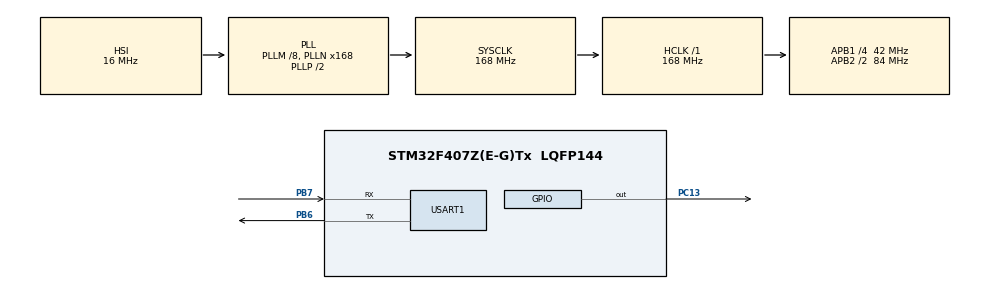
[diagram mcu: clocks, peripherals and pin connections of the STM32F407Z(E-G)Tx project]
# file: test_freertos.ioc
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Dma.Request0=USART1_TX
Dma.USART1_TX.0.Direction=DMA_MEMORY_TO_PERIPH
Dma.USART1_TX.0.FIFOMode=DMA_FIFOMODE_DISABLE
Dma.USART1_TX.0.Instance=DMA2_Stream7
Dma.USART1_TX.0.MemDataAlignment=DMA_MDATAALIGN_BYTE
Dma.USART1_TX.0.MemInc=DMA_MINC_ENABLE
Dma.USART1_TX.0.Mode=DMA_NORMAL
Dma.USART1_TX.0.PeriphDataAlignment=DMA_PDATAALIGN_BYTE
Dma.USART1_TX.0.PeriphInc=DMA_PINC_DISABLE
Dma.USART1_TX.0.Priority=DMA_PRIORITY_LOW
FREERTOS.Tasks01=defaultTask,24,128,StartDefaultTask,Default,NULL,Dynamic,NULL,NULL
Mcu.Family=STM32F4
Mcu.Name=STM32F407Z(E-G)Tx
Mcu.Package=LQFP144
NVIC.DMA2_Stream7_IRQn=true\:5\:0\:false\:false\:true\:true\:false\:true
NVIC.PriorityGroup=NVIC_PRIORITYGROUP_4
NVIC.TIM1_UP_TIM10_IRQn=true\:15\:0\:false\:false\:true\:false\:false\:true
NVIC.TimeBase=TIM1_UP_TIM10_IRQn
NVIC.TimeBaseIP=TIM1
PB6.Mode=Asynchronous
PB6.Signal=USART1_TX
PB7.Mode=Asynchronous
PB7.Signal=USART1_RX
PC13-ANTI_TAMP.Signal=GPIO_Output
ProjectManager.HeapSize=0x200
ProjectManager.StackSize=0x400
ProjectManager.TargetToolchain=Makefile
RCC.48MHZClocksFreq_Value=84000000
RCC.AHBFreq_Value=168000000
RCC.APB1CLKDivider=RCC_HCLK_DIV4
RCC.APB1Freq_Value=42000000
RCC.APB1TimFreq_Value=84000000
RCC.APB2CLKDivider=RCC_HCLK_DIV2
RCC.APB2Freq_Value=84000000
RCC.APB2TimFreq_Value=168000000
RCC.CortexFreq_Value=168000000
RCC.HCLKFreq_Value=168000000
RCC.HSE_VALUE=25000000
RCC.HSI_VALUE=16000000
RCC.LSE_VALUE=32768
RCC.PLLM=8
RCC.PLLN=168
RCC.SYSCLKFreq_VALUE=168000000
RCC.SYSCLKSource=RCC_SYSCLKSOURCE_PLLCLK
RCC.VCOOutputFreq_Value=336000000
USART1.VirtualMode=VM_ASYNC
VP_FREERTOS_VS_CMSIS_V2.Mode=CMSIS_V2
VP_SYS_VS_tim1.Mode=TIM1
board=custom

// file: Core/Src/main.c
/* USER CODE BEGIN Header */
/**
  ******************************************************************************
  * @file           : main.c
  * @brief          : Main program body
  ******************************************************************************
  * @attention
  *
  * <h2><center>&copy; Copyright (c) 2021 STMicroelectronics.
  * All rights reserved.</center></h2>
  *
  * This software component is licensed by ST under Ultimate Liberty license
  * SLA0044, the "License"; You may not use this file except in compliance with
  * the License. You may obtain a copy of the License at:
  *                             www.st.com/SLA0044
  *
  ******************************************************************************
  */
/* USER CODE END Header */
#include "main.h"
// #include "cmsis_os.h"

/* USER CODE BEGIN Includes */
#include "FreeRTOS.h"
#include "task.h"
#include "timers.h"
#include "semphr.h"
/* USER CODE END Includes */

UART_HandleTypeDef huart1;
DMA_HandleTypeDef hdma_usart1_tx;

/* Definitions for defaultTask */
// osThreadId_t defaultTaskHandle;
// const osThreadAttr_t defaultTask_attributes = {
//   .name = "defaultTask",
//   .stack_size = 128 * 4,
//   // .priority = (osPriority_t) osPriorityNormal,
// };
/* USER CODE BEGIN PV */
static SemaphoreHandle_t mutex;
/* USER CODE END PV */

void SystemClock_Config(void);
static void MX_GPIO_Init(void);
static void MX_USART1_UART_Init(void);
static void MX_DMA_Init(void);
void StartDefaultTask(void *argument);

/* USER CODE BEGIN 0 */
void vTask1( void *pvParameters )
{
  const char *pcTaskName = "Task 1";
  char buf[50];
  uint32_t ul=0; /* volatile to ensure ul is not optimized away. */
  /* As per most tasks, this task is implemented in an infinite loop. */
  for( ;; )
  {
    sprintf(buf,"%s: %d \r\n",pcTaskName,ul);
    // Take the mutex
    xSemaphoreTake(mutex, portMAX_DELAY);
    /* Print out the name of this task. */
    HAL_UART_Transmit(&huart1, buf, sizeof(char)*strlen(buf), HAL_MAX_DELAY);
    // HAL_UART_Transmit_DMA(&huart1, pcTaskName, sizeof(pcTaskName)); //Non-blocking mode with DMA
    // Release the mutex so that the creating function can finish
    xSemaphoreGive(mutex);
    vTaskDelay(1000);
    HAL_GPIO_TogglePin(GPIOC, GPIO_PIN_13);
    ul++;
    /* Delay for a period. */
    // for( ul = 0; ul < 1000; ul++ )
    // {
    //   /* This loop is just a very crude delay implementation. There is
    //   nothing to do in here. Later examples will replace this crude
    //   loop with a proper delay/sleep function. */
    // }
  }
}

void vTask2( void *pvParameters )
{
  const char *pcTaskName = "Task 2";
  char buf[50];
  uint32_t ul=0; /* volatile to ensure ul is not optimized away. */
  /* As per most tasks, this task is implemented in an infinite loop. */
  for( ;; )
  {
    sprintf(buf,"%s: %d \r\n",pcTaskName,ul);
    // Take the mutex
    xSemaphoreTake(mutex, portMAX_DELAY);
    /* Print out the name of this task. */
    HAL_UART_Transmit(&huart1, buf, sizeof(char)*strlen(buf), HAL_MAX_DELAY);
    // Release the mutex so that the creating function can finish
    xSemaphoreGive(mutex);
    // HAL_UART_Transmit_DMA(&huart1, pcTaskName, sizeof(pcTaskName)); //Non-blocking mode with DMA
    vTaskDelay(2000);
    ul++;
    // HAL_GPIO_TogglePin(GPIOC, GPIO_PIN_13);
    /* Delay for a period. */
    // for( ul = 0; ul < 500; ul++ )
    // {
    //   /* This loop is just a very crude delay implementation. There is
    //   nothing to do in here. Later examples will replace this crude
    //   loop with a proper delay/sleep function. */
    // }
  }
}
/* USER CODE END 0 */

int main(void)
{

  /* MCU Configuration--------------------------------------------------------*/

  /* Reset of all peripherals, Initializes the Flash interface and the Systick. */
  HAL_Init();

  /* Configure the system clock */
  SystemClock_Config();

  /* Initialize all configured peripherals */
  MX_GPIO_Init();
  MX_USART1_UART_Init();
  MX_DMA_Init();

  /* Init scheduler */
  // osKernelInitialize();

  /* Create the thread(s) */
  /* creation of defaultTask */
  // defaultTaskHandle = osThreadNew(StartDefaultTask, NULL, &defaultTask_attributes);

  /* Start scheduler */
  // osKernelStart();

  /* We should never get here as control is now taken by the scheduler */
  /* Infinite loop */
  /* USER CODE BEGIN WHILE */
  // HAL_GPIO_TogglePin(GPIOC, GPIO_PIN_13);
  // HAL_Delay(1000);
  // // vTaskDelay(1000);
  // // for(int i=0;i<100000000;i++);
  // HAL_GPIO_TogglePin(GPIOC, GPIO_PIN_13);
  // HAL_Delay(1000);
  // // vTaskDelay(1000);
  // // for(int i=0;i<100000000;i++);
  // HAL_GPIO_TogglePin(GPIOC, GPIO_PIN_13);
  // HAL_Delay(1000);
  // // vTaskDelay(1000);
  // // for(int i=0;i<100000000;i++);
  // HAL_GPIO_TogglePin(GPIOC, GPIO_PIN_13);
  // HAL_Delay(1000);
  // // vTaskDelay(1000);
  // // for(int i=0;i<100000000;i++);
  // HAL_GPIO_TogglePin(GPIOC, GPIO_PIN_13);
  // HAL_Delay(1000);
  // vTaskDelay(1000);
  // for(int i=0;i<100000000;i++);

  // Create mutex before starting tasks
  mutex = xSemaphoreCreateMutex();
  // Give the mutex
  xSemaphoreGive(mutex);

  char data[50] = {"Creating tasks...\r\n"};
  // uint8_t datalen = strlen(data)+48; //suma "0" en ASCII para que se imprima correctamente
  HAL_UART_Transmit(&huart1, &data, sizeof(char)*strlen(data), HAL_MAX_DELAY);

  xTaskCreate( vTask1, /* Pointer to the function that implements the task. */
              "Task 1",/* Text name for the task. This is to facilitate
              debugging only. */
              1000, /* Stack depth - small microcontrollers will use much
              less stack than this. */
              NULL, /* This example does not use the task parameter. */
              1, /* This task will run at priority 1. */
              NULL ); /* This example does not use the task handle. */
  /* Create the other task in exactly the same way and at the same priority. */
  xTaskCreate( vTask2, "Task 2", 1000, NULL, 1, NULL );
  /* Start the scheduler so the tasks start executing. */

  strcpy(data, "Starting Scheduler... \r\n");
  HAL_UART_Transmit(&huart1, &data, sizeof(char)*strlen(data), HAL_MAX_DELAY);
  vTaskStartScheduler();

  while (1)
  {
    /* USER CODE END WHILE */

  }
}

void SystemClock_Config(void)
{
  RCC_OscInitTypeDef RCC_OscInitStruct = {0};
  RCC_ClkInitTypeDef RCC_ClkInitStruct = {0};

  /** Configure the main internal regulator output voltage
  */
  __HAL_RCC_PWR_CLK_ENABLE();
  __HAL_PWR_VOLTAGESCALING_CONFIG(PWR_REGULATOR_VOLTAGE_SCALE1);
  /** Initializes the RCC Oscillators according to the specified parameters
  * in the RCC_OscInitTypeDef structure.
  */
  RCC_OscInitStruct.OscillatorType = RCC_OSCILLATORTYPE_HSI;
  RCC_OscInitStruct.HSIState = RCC_HSI_ON;
  RCC_OscInitStruct.HSICalibrationValue = RCC_HSICALIBRATION_DEFAULT;
  RCC_OscInitStruct.PLL.PLLState = RCC_PLL_ON;
  RCC_OscInitStruct.PLL.PLLSource = RCC_PLLSOURCE_HSI;
  RCC_OscInitStruct.PLL.PLLM = 8;
  RCC_OscInitStruct.PLL.PLLN = 168;
  RCC_OscInitStruct.PLL.PLLP = RCC_PLLP_DIV2;
  RCC_OscInitStruct.PLL.PLLQ = 4;
  if (HAL_RCC_OscConfig(&RCC_OscInitStruct) != HAL_OK)
  {
    Error_Handler();
  }
  /** Initializes the CPU, AHB and APB buses clocks
  */
  RCC_ClkInitStruct.ClockType = RCC_CLOCKTYPE_HCLK|RCC_CLOCKTYPE_SYSCLK
                              |RCC_CLOCKTYPE_PCLK1|RCC_CLOCKTYPE_PCLK2;
  RCC_ClkInitStruct.SYSCLKSource = RCC_SYSCLKSOURCE_PLLCLK;
  RCC_ClkInitStruct.AHBCLKDivider = RCC_SYSCLK_DIV1;
  RCC_ClkInitStruct.APB1CLKDivider = RCC_HCLK_DIV4;
  RCC_ClkInitStruct.APB2CLKDivider = RCC_HCLK_DIV2;

  if (HAL_RCC_ClockConfig(&RCC_ClkInitStruct, FLASH_LATENCY_5) != HAL_OK)
  {
    Error_Handler();
  }
}

static void MX_USART1_UART_Init(void)
{

  huart1.Instance = USART1;
  huart1.Init.BaudRate = 115200;
  huart1.Init.WordLength = UART_WORDLENGTH_8B;
  huart1.Init.StopBits = UART_STOPBITS_1;
  huart1.Init.Parity = UART_PARITY_NONE;
  huart1.Init.Mode = UART_MODE_TX_RX;
  huart1.Init.HwFlowCtl = UART_HWCONTROL_NONE;
  huart1.Init.OverSampling = UART_OVERSAMPLING_16;
  if (HAL_UART_Init(&huart1) != HAL_OK)
  {
    Error_Handler();
  }

}

static void MX_DMA_Init(void)
{

  /* DMA controller clock enable */
  __HAL_RCC_DMA2_CLK_ENABLE();

  /* DMA interrupt init */
  /* DMA2_Stream7_IRQn interrupt configuration */
  HAL_NVIC_SetPriority(DMA2_Stream7_IRQn, 5, 0);
  HAL_NVIC_EnableIRQ(DMA2_Stream7_IRQn);

}

static void MX_GPIO_Init(void)
{
  GPIO_InitTypeDef GPIO_InitStruct = {0};

  /* GPIO Ports Clock Enable */
  __HAL_RCC_GPIOC_CLK_ENABLE();
  __HAL_RCC_GPIOB_CLK_ENABLE();

  /*Configure GPIO pin Output Level */
  HAL_GPIO_WritePin(GPIOC, GPIO_PIN_13, GPIO_PIN_RESET);

  /*Configure GPIO pin : PC13 */
  GPIO_InitStruct.Pin = GPIO_PIN_13;
  GPIO_InitStruct.Mode = GPIO_MODE_OUTPUT_PP;
  GPIO_InitStruct.Pull = GPIO_NOPULL;
  GPIO_InitStruct.Speed = GPIO_SPEED_FREQ_LOW;
  HAL_GPIO_Init(GPIOC, &GPIO_InitStruct);

}

void StartDefaultTask(void *argument)
{
  /* USER CODE BEGIN 5 */
  /* Infinite loop */
  for(;;)
  {
    vTaskDelay(1);
  }
  /* USER CODE END 5 */
}

void HAL_TIM_PeriodElapsedCallback(TIM_HandleTypeDef *htim)
{
  if (htim->Instance == TIM1) {
    HAL_IncTick();
  }
}

void Error_Handler(void)
{
  __disable_irq();
  while (1)
  {
  }
}

/************************ (C) COPYRIGHT STMicroelectronics *****END OF FILE****/
